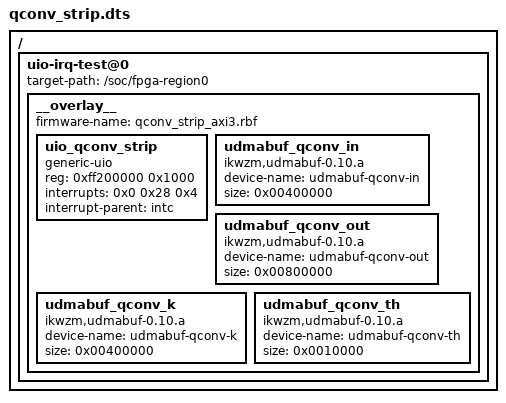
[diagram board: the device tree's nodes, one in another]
/dts-v1/; /plugin/;
/ {
	uio-irq-test@0 {
		target-path = "/soc/fpga-region0";
		#address-cells = <0x1>;
		#size-cells = <0x1>;
		
		__overlay__ {
			#address-cells = <0x1>;
			#size-cells = <0x1>;

			firmware-name = "qconv_strip_axi3.rbf";
			
			uio_qconv_strip {
				compatible = "generic-uio";
				reg = <0xff200000 0x1000>;
				interrupts = <0x0 0x28 0x4>;
				interrupt-parent = <&intc>;
	                };

			udmabuf_qconv_in {
				compatible  = "ikwzm,udmabuf-0.10.a";
				device-name = "udmabuf-qconv-in";
				size = <0x00400000>;
	                };

			udmabuf_qconv_out {
				compatible = "ikwzm,udmabuf-0.10.a";
				device-name = "udmabuf-qconv-out";
				size = <0x00800000>;
			};
			
			udmabuf_qconv_k {
				compatible = "ikwzm,udmabuf-0.10.a";
				device-name = "udmabuf-qconv-k";
				size = <0x00400000>;
			};

			udmabuf_qconv_th {
				compatible = "ikwzm,udmabuf-0.10.a";
				device-name = "udmabuf-qconv-th";
				size = <0x0010000>;
			};
                };
	} ;
} ;
